# SC32F10T_10G register map
File version: 1.0
CPU: CM0+ r0p1, little endian, MPU, no FPU, 4 interrupt priority bits
Registers are 32-bit, access not given, reset 0x0 unless marked. A register's access mark holds for its fields unless they carry their own. Offsets are from the block's base; [hi:lo] are bit positions; 'fields as' and 'values as' point back to an identical list.

## TWI1
Base 0x40021060
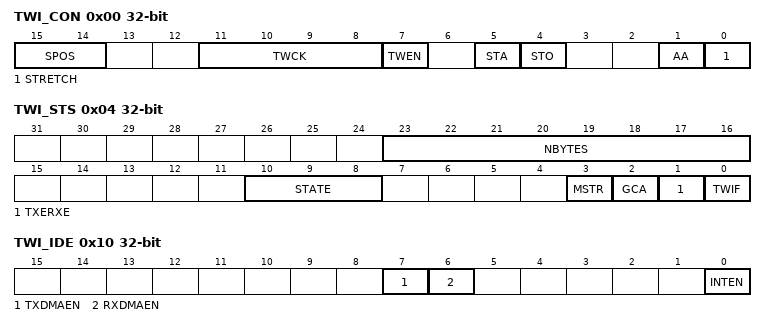
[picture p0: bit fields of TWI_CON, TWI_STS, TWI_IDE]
0x00 TWI_CON rw — TWI控制寄存器
  [15:14] SPOS — TWI0信号口映射控制位@TWI0_CON 信号SPOS值SCL0SDA0SPOS[1:0]=00PB1PB0SPOS[1:0]=01PC10PC11SPOS[1:0]=10PA6PA5SPOS[1:0]=11PA13PA14TWI1信号口映射控制位@TWI1_CON
  [11:8] TWCK — 主机模式下TWI的通信速率设定：0000：fPCLK /4096 0001：fPCLK /20480010：fPCLK /10240011：fPCLK /5120100：fPCLK /2560101：fPCLK /1280110：fPCLK /640111：fPCLK /321000：fPCLK /161001：fPCLK /81010：fPCLK /4其它：fPCLK /4TWI0的通信速率fT
  [7] TWEN — TWI使能控制位0：关闭TWI1：打开TWI
  [5] STA — TWI起始位触发开关该位写1将产生起始条件，TWI将切换为主机模式。软件可以设置或清除该位，或当起始条件发出后，由硬件清0。
  [4] STO — TWI停止位触发开关主机模式下，对该位写1，在当前字节传输或起始条件发出后产生停止条件。软件可以设置或清除该位，或当检测到停止条件时，由硬件清除。
  [1] AA — TWI应答使能位0：无应答，返回UACK（应答位为高电平）1：在接收到一个匹配的地址或数据后返回一个应答ACK
  [0] STRETCH — TWI时钟延长使能位该位仅在从机模式下有效0：禁止时钟延长1：允许时钟延长，主机需要支持时钟延长功能说明：在数据传输完成之后，且ACK为0，此时时钟延长发生。
0x04 TWI_STS rw — TWI标志位寄存器
  [23:16] NBYTES — 收发缓存字节数设置位用于设置待发送/接收的字节数。每发送/接收成功一个自己NBYTES自动减1，当NBYTES为0时TC标志位将置起。注意：STA置1时不允许修改。
  [10:8] STATE — TWI状态位用于指示TWI状态，主/从机模式下状态位含义不同。从机模式：000：从机处于空闲状态，等待TWEN置1，检测TWI 启动信号。当从机接收到停止条件后跳转到此状态001：从机正在接收第一帧地址和读写位（第8位为读写位，1为读，0为写）。从机接收到起始条件后会跳转到此状态010：从机接收数据状态011：从机发送数据状态100：在从机发送数据状态中，当主机回UACK时跳转到此状态，等待重新启
  [3] MSTR — TWI主/从机模式标志位0：从机模式1：主机模式说明：当TWI接口向总线发出起始条件后，会自动切换为主机模式，同时硬件将该位置位；当总线上检测到一个停止条件时，硬件清除该位。
  [2] GCA — TWI通用地址响应标志位0：非响应通用地址1：当GC置1，同时通用地址匹配时该位由硬件置1，并自动清0
  [1] TXERXE — TWI传输完成标志位以下情况，TXnE/RXnE由硬件置1主机模式：主机发送地址帧（写），且收到从机的ACK主机发送完数据，且接收到从机ACK主机接收到数据，且主机回从机ACK从机模式：从机接收地址帧（读），且和从机地址（TWA）匹配从机接收到数据，且从机回主机ACK从机发送完数据，且接收到主机ACK（AA=1）对TWIDAT进行读写操作后，该位将被硬件清除。
  [0] TWIF — TWI中断标志位该位由硬件置1，通过软件写1清0。主机模式：发送启动信号发送完地址帧接收或发送完数据帧从机模式：第一帧地址匹配成功成功接收或发送8位数据接收到重复起始条件从机收到停止信号
0x08 TWI_ADD — TWI地址寄存器
0x0C TWI_DATA — TWI数据寄存器
0x10 TWI_IDE rw — 通信口DMA控制寄存器
  [7] TXDMAEN — DMA发送通道使能位0：禁用DMA发送功能1：使能DMA发送功能该位使能后，TXnE/RXnE置起可触发DMA通道发送请求注意：TWI0可产生DMA请求TWI1不能产生DMA请求
  [6] RXDMAEN — DMA接收通道使能位0：禁用DMA接收功能1：使能DMA接收功能该位使能后，TXnE/RXnE置起可触发DMA通道接收请求注意：TWI0可产生DMA请求TWI1不能产生DMA请求
  [0] INTEN — 中断请求 CPU的使能控制位0：禁止中断请求1：使能中断请求

## TIM0
Base 0x40020100
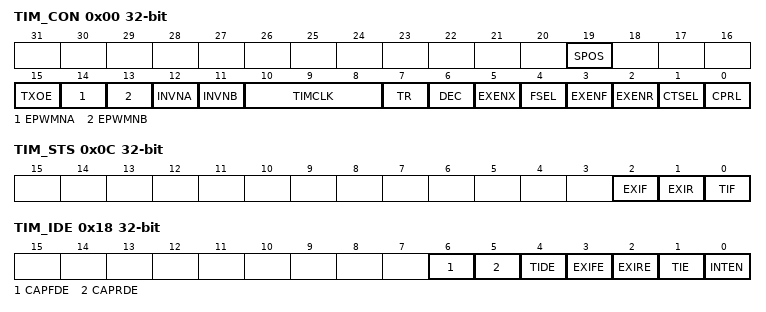
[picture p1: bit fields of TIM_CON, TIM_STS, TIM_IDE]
0x00 TIM_CON rw — 定时器控制寄存器
  [19] SPOS — TIM2管脚映射控制位@ TIM2_CON 信号SPOS值T2CAP/T2SPOS=0PA10SPOS=1PA12TIM3管脚映射控制位@ TIM3_CON 信号SPOS值T3CAP/T3SPOS=0PA0SPOS=1PA13TIM7管脚映射控制位@ TIM7
  [15] TXOE — Tn引脚信号方向控制位0：Tn作为时钟输入口或I/O 端口1：Tn用于可编程时钟输出
  [14] EPWMNA — Tn_PWMA所在管脚 PWM波形输出使能位0：关闭1：使能
  [13] EPWMNB — TnEX_PWMB所在管脚 PWM波形输出使能位0：关闭1：使能
  [12] INVNA — TPWMnA波形输出反向控制位0：正常1：波形输出反向
  [11] INVNB — TPWMnB波形输出反向控制位0：正常1：波形输出反向
  [10:8] TIMCLK — TIM时钟频率档位控制位000：fTIM/1001：fTIM/2010：fTIM/4011：fTIM/8100：fTIM/16101：fTIM/32110：fTIM/64111：fTIM/128fTIM对应的时钟可能为fPCLK 或Tn输入
  [7] TR — TIMn开始/停止控制位，n=0~7 0：停止TIMn / TPWMn计数器 1：开始TIMn / TPWMn计数器
  [6] DEC — 递增/递减方向控制位 0：TIMn为递增的定时/计数器 1：TIMn作为递增/递减的定时/计数器，TnEX用来选择计数方向
  [5] EXENX — TnEX设置位，n=0该位在不同模式下作用不同：重载模式：（CPRL = 0） 该位用于控制TnEX引脚上的外部事件输入(下降沿)，用作重载允许/禁止控制： 0：忽略TnEX引脚上的事件 1：检测到TnEX引脚上一个下降沿，产生一个重载捕获模式：（CPRL = 1） 该位用作TnEX下降沿信号捕获选通位： 0：忽略TnEX引脚上的事件 1：当FSEL = 1，检测到TnEX引脚上一个下降沿，产生一
  [4] FSEL — 下降沿信号选择位该位仅在捕获模式（CPRL=1)下有效 0：检测到Tn引脚上一个下降沿，产生一个捕获。忽略TnEX引脚上的事件 1：检测到TnEX引脚上一个下降沿，产生一个捕获。忽略Tn引脚上的事件
  [3] EXENF — 下降沿信号捕获使能位:0：忽略Tn引脚上的事件 1：检测到Tn引脚上一个下降沿，产生一个捕获，EXIF被置起，TnCNT寄存器的值捕获到寄存器FCAP里
  [2] EXENR — Tn引脚上的上升沿信号捕获使能位 0：忽略Tn引脚上的事件 1：检测到Tn引脚上一个上升沿，产生一个捕获，EXIR被置起，TnCNT寄存器的值捕获到寄存器RCAP里
  [1] CTSEL — 定时器/计数器选定位 0：定时器方式 1：计数器方式
  [0] CPRL — 捕获/重载方式设置位 0：重载功能 1：捕获功能
0x04 TIM_CNT — 定时器计数值寄存器
0x08 TIM_RLD — 定时器重载寄存器
0x0C TIM_STS rw — 定时器标志位寄存器
  [2] EXIF — 外部事件输入下降沿被检测到的标志位该位由硬件置1，通过软件写1清0。 0：无外部事件输入 1：检测到外部输入(如果EXENF = 1，由硬件设1) 注意：捕获模式下，该位软件清0之前不允许更新TnFCAP值
  [1] EXIR — Tn引脚外部事件输入上升沿被检测到的标志位该位由硬件置1，通过软件写1清0。 0：无外部事件输入 1：检测到外部输入(如果EXENR = 1，由硬件设1) 注意：捕获模式下，该位软件清0之前不允许更新TnRCAP值
  [0] TIF — 定时器溢出标志位该位由硬件置1，通过软件写1清0。 0：无溢出(必须由软件清0) 1：溢出(如果RCLK = 0和TCLK = 0，由硬件设1)
0x10 TIM_PDTA_RCAP — TIMER Rise Caputre Key register
0x14 TIM_PDTB_FCAP — TIMER fall Caputre register
0x18 TIM_IDE rw — TIMn的中断使能及DMA控制寄存器
  [6] CAPFDE — 下降沿捕获事件触发DMA请求使能位 0：下降沿捕获事件禁止产生DMA请求 1：产生新的下降沿捕获时，触发DMA请求，DMA搬运FCAP寄存器的值
  [5] CAPRDE — 上升沿捕获事件触发DMA请求使能位 0：上升沿捕获事件禁止产生DMA请求 1：产生新的下降沿捕获时，触发DMA请求，DMA搬运RCAP寄存器的值
  [4] TIDE — 定时器溢出事件触发DMA请求使能位 0：定时器溢出禁止产生DMA请求 1：定时器溢出允许产生DMA请求
  [3] EXIFE — 外部事件输入下降沿中断开关 0：禁止下降沿中断 1：使能下降沿中断
  [2] EXIRE — 外部事件输入上升沿中断开关 0：禁止上升沿中断 1：使能上升沿中断
  [1] TIE — 定时器溢出中断开关 0：禁止溢出中断 1：使能溢出中断
  [0] INTEN — 中断请求 CPU的使能控制位0：禁止中断请求1：使能中断请求

## TIM1
Base 0x40020140
Same registers: TIM4 0x40021100, TIM5 0x40021140, TIM6 0x40021180
Registers as TIM0; these are added or differ:
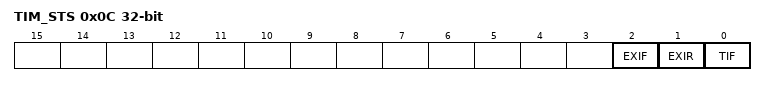
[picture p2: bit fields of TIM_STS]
0x0C TIM_STS rw — 定时标志位寄存器
  fields as TIM0.TIM_STS
